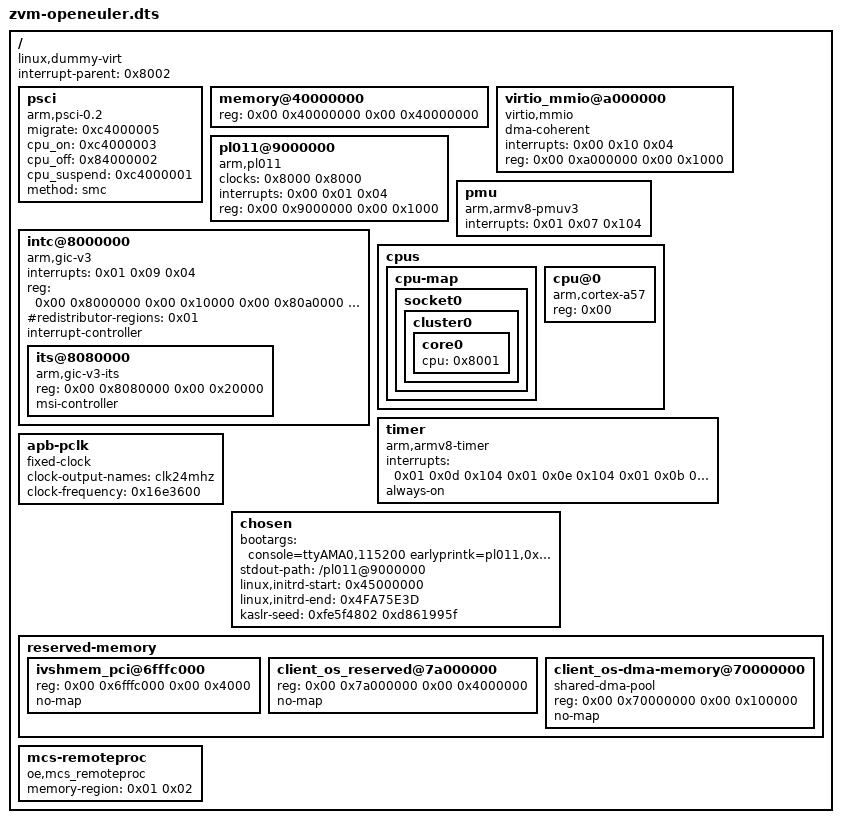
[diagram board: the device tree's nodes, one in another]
/dts-v1/;

/ {
	interrupt-parent = <0x8002>;
	#size-cells = <0x02>;
	#address-cells = <0x02>;
	compatible = "linux,dummy-virt";

	psci {
		migrate = <0xc4000005>;
		cpu_on = <0xc4000003>;
		cpu_off = <0x84000002>;
		cpu_suspend = <0xc4000001>;
		method = "smc";
		compatible = "arm,psci-0.2\0arm,psci";
	};

	memory@40000000 {
		reg = <0x00 0x40000000 0x00 0x40000000>;
		device_type = "memory";
	};

	virtio_mmio@a000000 {
		dma-coherent;
		interrupts = <0x00 0x10 0x04>;
		reg = <0x00 0xa000000 0x00 0x1000>;
		compatible = "virtio,mmio";
	};

	pl011@9000000 {
		clock-names = "uartclk\0apb_pclk";
		clocks = <0x8000 0x8000>;
		interrupts = <0x00 0x01 0x04>;
		reg = <0x00 0x9000000 0x00 0x1000>;
		compatible = "arm,pl011\0arm,primecell";
	};

	pmu {
		interrupts = <0x01 0x07 0x104>;
		compatible = "arm,armv8-pmuv3";
	};

	intc@8000000 {
		phandle = <0x8002>;
		interrupts = <0x01 0x09 0x04>;
		reg = <0x00 0x8000000 0x00 0x10000 0x00 0x80a0000 0x00 0xf60000>;
		#redistributor-regions = <0x01>;
		compatible = "arm,gic-v3";
		ranges;
		#size-cells = <0x02>;
		#address-cells = <0x02>;
		interrupt-controller;
		#interrupt-cells = <0x03>;

		its@8080000 {
			phandle = <0x8003>;
			reg = <0x00 0x8080000 0x00 0x20000>;
			msi-controller;
			compatible = "arm,gic-v3-its";
		};
	};

	cpus {
		#size-cells = <0x00>;
		#address-cells = <0x01>;

		cpu-map {

			socket0 {

				cluster0 {

					core0 {
						cpu = <0x8001>;
					};
				};
			};
		};

		cpu@0 {
			phandle = <0x8001>;
			reg = <0x00>;
			compatible = "arm,cortex-a57";
			device_type = "cpu";
		};
	};

	timer {
		interrupts = <0x01 0x0d 0x104 0x01 0x0e 0x104 0x01 0x0b 0x104 0x01 0x0a 0x104>;
		always-on;
		compatible = "arm,armv8-timer\0arm,armv7-timer";
	};

	apb-pclk {
		phandle = <0x8000>;
		clock-output-names = "clk24mhz";
		clock-frequency = <0x16e3600>;
		#clock-cells = <0x00>;
		compatible = "fixed-clock";
	};

	chosen {
		bootargs = "console=ttyAMA0,115200 earlyprintk=pl011,0x9000000 root=/dev/ram0 init=/sbin/init ramdisk_size=10000000 rootfstype=cpio rw";
		stdout-path = "/pl011@9000000";
		linux,initrd-start = <0x45000000>;
		linux,initrd-end = <0x4FA75E3D>;
		kaslr-seed = <0xfe5f4802 0xd861995f>;
	};

	reserved-memory {
		#address-cells = <0x02>;
		#size-cells = <0x02>;
		ranges;

		ivshmem_pci@6fffc000 {
			reg = <0x00 0x6fffc000 0x00 0x4000>;
			no-map;
		};

		client_os_reserved@7a000000 {
			reg = <0x00 0x7a000000 0x00 0x4000000>;
			no-map;
			phandle = <0x02>;
		};

		client_os-dma-memory@70000000 {
			compatible = "shared-dma-pool";
			reg = <0x00 0x70000000 0x00 0x100000>;
			no-map;
			phandle = <0x01>;
		};
	};

	mcs-remoteproc {
		compatible = "oe,mcs_remoteproc";
		memory-region = <0x01 0x02>;
	};
};
